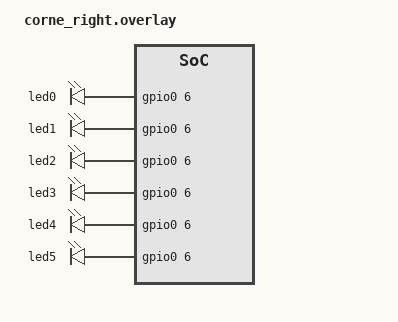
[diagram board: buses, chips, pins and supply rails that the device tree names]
/ {
    chosen {
        zmk,backlight = &backlight_leds;
        zmk,underglow = &underglow;
        zmk,studio = &studio_endpoint;
    };

    studio_endpoint: studio {
        compatible = "zmk,studio";
    };

    backlight_leds: leds {
        compatible = "gpio-leds";

        led0 { gpios = <&gpio0 6 GPIO_ACTIVE_HIGH>; };
        led1 { gpios = <&gpio0 6 GPIO_ACTIVE_HIGH>; };
        led2 { gpios = <&gpio0 6 GPIO_ACTIVE_HIGH>; };
        led3 { gpios = <&gpio0 6 GPIO_ACTIVE_HIGH>; };
        led4 { gpios = <&gpio0 6 GPIO_ACTIVE_HIGH>; };
        led5 { gpios = <&gpio0 6 GPIO_ACTIVE_HIGH>; };
    };

    underglow: underglow {
        compatible = "zmk,rgb-underglow";
        chain-length = <21>;
    };
};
